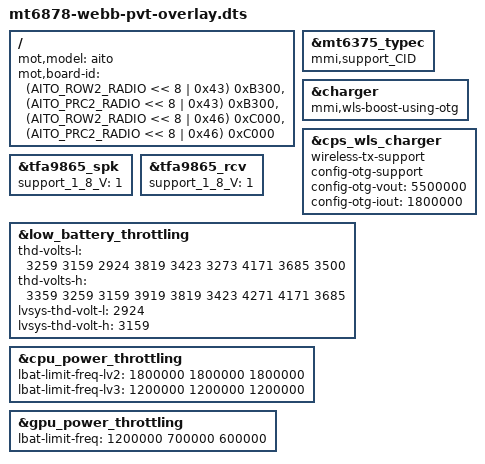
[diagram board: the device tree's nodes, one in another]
/* Copyright (c) 2023, Motorola Mobility Inc. All rights reserved.
 *
 * This program is free software; you can redistribute it and/or modify
 * it under the terms of the GNU General Public License version 2 and
 * only version 2 as published by the Free Software Foundation.
 *
 * This program is distributed in the hope that it will be useful,
 * but WITHOUT ANY WARRANTY; without even the implied warranty of
 * MERCHANTABILITY or FITNESS FOR A PARTICULAR PURPOSE.  See the
 * GNU General Public License for more details.
 */

/dts-v1/;
/plugin/;

#include "mediatek/mt6878-aito-common-overlay.dtsi"

#define AITO_ROW2_RADIO 7
#define AITO_PRC2_RADIO 8

/* Board match root node */
/ {
	fragment@model {
		target-path = "/";
		__overlay__ {
			mot,model = "aito";
			mot,board-id = <(AITO_ROW2_RADIO << 8 | 0x43) 0xB300>, <(AITO_PRC2_RADIO << 8 | 0x43) 0xB300>, <(AITO_ROW2_RADIO << 8 | 0x46) 0xC000>, <(AITO_PRC2_RADIO << 8 | 0x46) 0xC000>;
		};
	};
};

&mt6375_typec {
       mmi,support_CID;
};

&charger {
	mmi,wls-boost-using-otg;
};

&cps_wls_charger {
	wireless-tx-support;
	config-otg-support;
	config-otg-vout = <5500000>;
	config-otg-iout = <1800000>;
};

&tfa9865_spk {
    support_1_8_V=<1>;
};

&tfa9865_rcv {
    support_1_8_V=<1>;
};

&low_battery_throttling {
	thd-volts-l = <
		3259 3159 2924
		3819 3423 3273
		4171 3685 3500>;
	thd-volts-h = <
		3359 3259 3159
		3919 3819 3423
		4271 4171 3685>;
	lvsys-thd-volt-l = <2924>;
	lvsys-thd-volt-h = <3159>;
};

&cpu_power_throttling {
	lbat-limit-freq-lv2 = < 1800000  1800000 1800000>;
	lbat-limit-freq-lv3 = < 1200000  1200000 1200000>;
};

&gpu_power_throttling {
	lbat-limit-freq = <1200000 700000 600000>;
};

#include <aito_pvt/cust.dtsi>
/*End of this file, DO NOT ADD ANYTHING HERE*/
